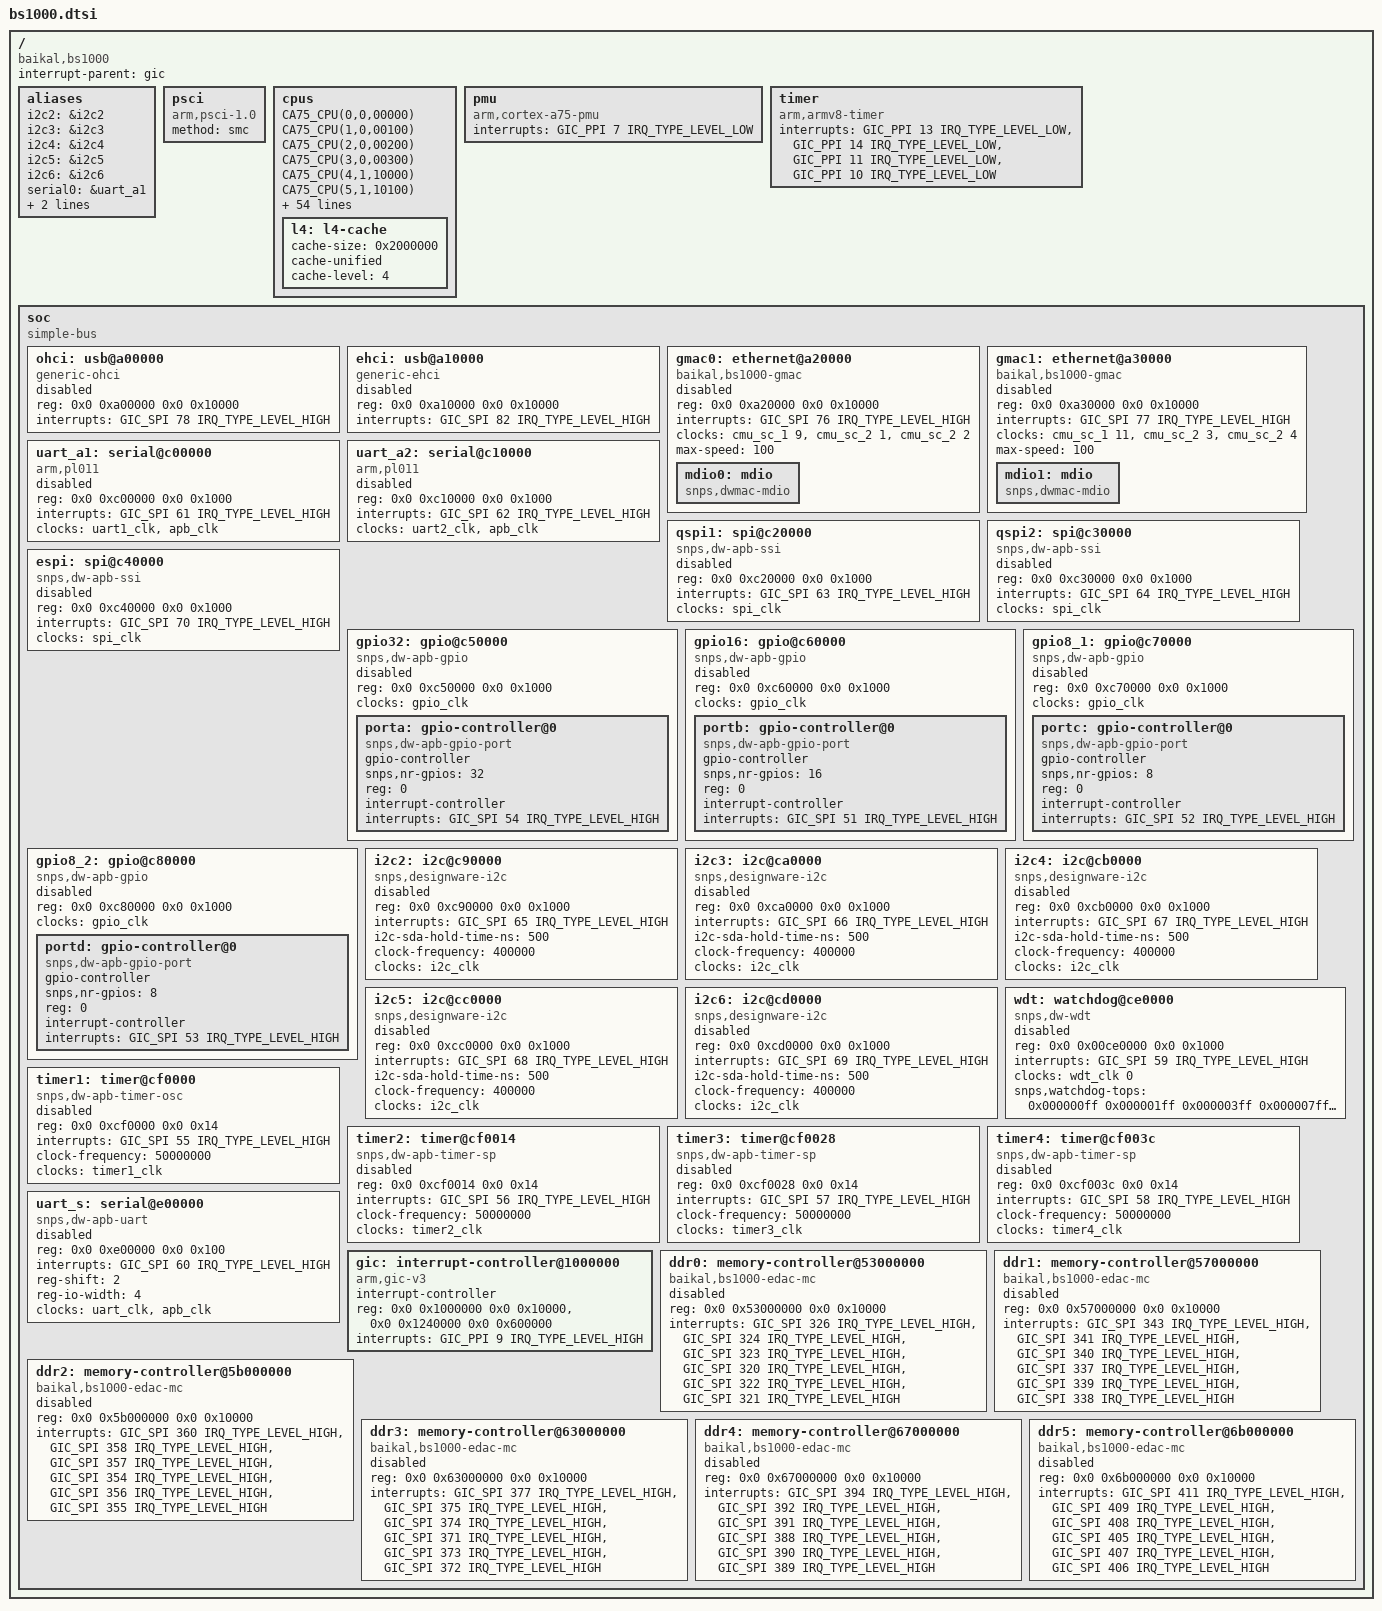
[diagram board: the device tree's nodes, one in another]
// SPDX-License-Identifier: GPL-2.0
/*
 * Device tree include file for BE-S1000 SoC
 * Copyright (C) 2021 Baikal Electronics, JSC
 */

#include <dt-bindings/interrupt-controller/arm-gic.h>
#include "bs1000-clocks.dtsi"

#define CA75_CPU(core, cluster, affinity)		\
	cpu##core: cpu@##affinity {			\
		device_type = "cpu";			\
		compatible = "arm,cortex-a75";		\
		reg = <0x0 0x##affinity>;		\
		enable-method = "psci";			\
		i-cache-size = <0x10000>;		\
		i-cache-line-size = <64>;		\
		i-cache-sets = <256>;			\
		d-cache-size = <0x10000>;		\
		d-cache-line-size = <64>;		\
		d-cache-sets = <64>;			\
		next-level-cache = <&l2_##core>;	\
		L2_CACHE(core, cluster);		\
	}

#define L2_CACHE(core, cluster)				\
	l2_##core: l2-cache {				\
		compatible = "cache";			\
		cache-size = <0x80000>;			\
		cache-line-size = <64>;			\
		cache-sets = <1024>;			\
		cache-unified;				\
		cache-level = <2>;			\
		next-level-cache = <&l3_##cluster>;	\
	}

#define L3_CACHE(cluster)				\
	l3_##cluster: l3-cache##cluster {		\
		compatible = "cache";			\
		cache-size = <0x200000>;		\
		cache-line-size = <64>;			\
		cache-sets = <2048>;			\
		cache-unified;				\
		cache-level = <3>;			\
		next-level-cache = <&l4>;		\
	}

/ {
	compatible = "baikal,bs1000";
	#address-cells = <2>;
	#size-cells = <2>;
	interrupt-parent = <&gic>;

	aliases {
		i2c2	= &i2c2;
		i2c3	= &i2c3;
		i2c4	= &i2c4;
		i2c5	= &i2c5;
		i2c6	= &i2c6;
		serial0	= &uart_a1;
		serial1	= &uart_a2;
		serial2	= &uart_s;
	};

	psci {
		compatible = "arm,psci-1.0", "arm,psci-0.2";
		method = "smc";
	};

	cpus {
		#address-cells = <2>;
		#size-cells = <0>;

		/* TODO: try to use 'cpu-map' */

		CA75_CPU(0,0,00000);
		CA75_CPU(1,0,00100);
		CA75_CPU(2,0,00200);
		CA75_CPU(3,0,00300);
		CA75_CPU(4,1,10000);
		CA75_CPU(5,1,10100);
		CA75_CPU(6,1,10200);
		CA75_CPU(7,1,10300);
		CA75_CPU(8,2,20000);
		CA75_CPU(9,2,20100);
		CA75_CPU(10,2,20200);
		CA75_CPU(11,2,20300);
		CA75_CPU(12,3,30000);
		CA75_CPU(13,3,30100);
		CA75_CPU(14,3,30200);
		CA75_CPU(15,3,30300);
		CA75_CPU(16,4,40000);
		CA75_CPU(17,4,40100);
		CA75_CPU(18,4,40200);
		CA75_CPU(19,4,40300);
		CA75_CPU(20,5,50000);
		CA75_CPU(21,5,50100);
		CA75_CPU(22,5,50200);
		CA75_CPU(23,5,50300);
		CA75_CPU(24,6,60000);
		CA75_CPU(25,6,60100);
		CA75_CPU(26,6,60200);
		CA75_CPU(27,6,60300);
		CA75_CPU(28,7,70000);
		CA75_CPU(29,7,70100);
		CA75_CPU(30,7,70200);
		CA75_CPU(31,7,70300);
		CA75_CPU(32,8,80000);
		CA75_CPU(33,8,80100);
		CA75_CPU(34,8,80200);
		CA75_CPU(35,8,80300);
		CA75_CPU(36,9,90000);
		CA75_CPU(37,9,90100);
		CA75_CPU(38,9,90200);
		CA75_CPU(39,9,90300);
		CA75_CPU(40,10,a0000);
		CA75_CPU(41,10,a0100);
		CA75_CPU(42,10,a0200);
		CA75_CPU(43,10,a0300);
		CA75_CPU(44,11,b0000);
		CA75_CPU(45,11,b0100);
		CA75_CPU(46,11,b0200);
		CA75_CPU(47,11,b0300);

		L3_CACHE(0);
		L3_CACHE(1);
		L3_CACHE(2);
		L3_CACHE(3);
		L3_CACHE(4);
		L3_CACHE(5);
		L3_CACHE(6);
		L3_CACHE(7);
		L3_CACHE(8);
		L3_CACHE(9);
		L3_CACHE(10);
		L3_CACHE(11);

		l4: l4-cache {
			cache-size = <0x2000000>;
			cache-unified;
			cache-level = <4>;
		};
	};

	pmu {
		compatible = "arm,cortex-a75-pmu", "arm,armv8-pmuv3";
		interrupts = <GIC_PPI 7 IRQ_TYPE_LEVEL_LOW>;
	};

	timer {
		compatible = "arm,armv8-timer";
		interrupts = <GIC_PPI 13 IRQ_TYPE_LEVEL_LOW>,
			     <GIC_PPI 14 IRQ_TYPE_LEVEL_LOW>,
			     <GIC_PPI 11 IRQ_TYPE_LEVEL_LOW>,
			     <GIC_PPI 10 IRQ_TYPE_LEVEL_LOW>;
	};

	soc {
		compatible = "simple-bus";
		#address-cells = <2>;
		#size-cells = <2>;
		ranges;

		ohci: usb@a00000 {
			compatible = "generic-ohci";
			reg = <0x0 0xa00000 0x0 0x10000>;
			interrupts = <GIC_SPI 78 IRQ_TYPE_LEVEL_HIGH>;
			status = "disabled";
		};

		ehci: usb@a10000 {
			compatible = "generic-ehci";
			reg = <0x0 0xa10000 0x0 0x10000>;
			interrupts = <GIC_SPI 82 IRQ_TYPE_LEVEL_HIGH>;
			status = "disabled";
		};

		gmac0: ethernet@a20000 {
			compatible = "baikal,bs1000-gmac";
			reg = <0x0 0xa20000 0x0 0x10000>;
			interrupts = <GIC_SPI 76 IRQ_TYPE_LEVEL_HIGH>;
			interrupt-names = "macirq";
			clocks = <&cmu_sc_1 9>, <&cmu_sc_2 1>, <&cmu_sc_2 2>;
			clock-names = "stmmaceth", "ptp_ref", "tx2_clk";
			max-speed = <100>;
			status = "disabled";

			mdio0: mdio {
				compatible = "snps,dwmac-mdio";
				#address-cells = <1>;
				#size-cells = <0>;
			};
		};

		gmac1: ethernet@a30000 {
			compatible = "baikal,bs1000-gmac";
			reg = <0x0 0xa30000 0x0 0x10000>;
			interrupts = <GIC_SPI 77 IRQ_TYPE_LEVEL_HIGH>;
			interrupt-names = "macirq";
			clocks = <&cmu_sc_1 11>, <&cmu_sc_2 3>, <&cmu_sc_2 4>;
			clock-names = "stmmaceth", "ptp_ref", "tx2_clk";
			max-speed = <100>;
			status = "disabled";

			mdio1: mdio {
				compatible = "snps,dwmac-mdio";
				#address-cells = <1>;
				#size-cells = <0>;
			};
		};

		uart_a1: serial@c00000 {
			compatible = "arm,pl011", "arm,primecell";
			reg = <0x0 0xc00000 0x0 0x1000>;
			interrupts = <GIC_SPI 61 IRQ_TYPE_LEVEL_HIGH>;
			clocks = <&uart1_clk>, <&apb_clk>;
			// clocks = <&cmu_sc_1 18>, <&cmu_sc_1 15>; // "lsp_uart_arm1", "lsp_apb"
			clock-names = "uartclk", "apb_pclk";
			status = "disabled";
		};

		uart_a2: serial@c10000 {
			compatible = "arm,pl011", "arm,primecell";
			reg = <0x0 0xc10000 0x0 0x1000>;
			interrupts = <GIC_SPI 62 IRQ_TYPE_LEVEL_HIGH>;
			clocks = <&uart2_clk>, <&apb_clk>;
			// clocks = <&cmu_sc_1 19>, <&cmu_sc_1 15>; // "lsp_uart_arm2", "lsp_apb"
			clock-names = "uartclk", "apb_pclk";
			status = "disabled";
		};

		qspi1: spi@c20000 {
			compatible = "snps,dw-apb-ssi";
			reg = <0x0 0xc20000 0x0 0x1000>;
			#address-cells = <1>;
			#size-cells = <0>;
			interrupts = <GIC_SPI 63 IRQ_TYPE_LEVEL_HIGH>;
			clocks = <&spi_clk>;
			// clocks = <&cmu_sc_1 20>; // "lsp_spi1"
			status = "disabled";
		};

		qspi2: spi@c30000 {
			compatible = "snps,dw-apb-ssi";
			reg = <0x0 0xc30000 0x0 0x1000>;
			#address-cells = <1>;
			#size-cells = <0>;
			interrupts = <GIC_SPI 64 IRQ_TYPE_LEVEL_HIGH>;
			clocks = <&spi_clk>;
			// clocks = <&cmu_sc_1 21>; // "lsp_spi2"
			status = "disabled";
		};

		espi: spi@c40000 {
			compatible = "snps,dw-apb-ssi";
			reg = <0x0 0xc40000 0x0 0x1000>;
			#address-cells = <1>;
			#size-cells = <0>;
			interrupts = <GIC_SPI 70 IRQ_TYPE_LEVEL_HIGH>;
			clocks = <&spi_clk>;
			// clocks = <&cmu_sc_1 22>; // "lsp_espi"
			status = "disabled";
		};

		gpio32: gpio@c50000 {
			compatible = "snps,dw-apb-gpio";
			reg = <0x0 0xc50000 0x0 0x1000>;
			#address-cells = <1>;
			#size-cells = <0>;
			clocks = <&gpio_clk>;
			// clocks = <&cmu_sc_1 16>; // "lsp_gpio_x16"
			status = "disabled";

			porta: gpio-controller@0 {
				compatible = "snps,dw-apb-gpio-port";
				gpio-controller;
				#gpio-cells = <2>;
				snps,nr-gpios = <32>;
				reg = <0>;
				interrupt-controller;
				#interrupt-cells = <2>;
				interrupts = <GIC_SPI 54 IRQ_TYPE_LEVEL_HIGH>;
			};
		};

		gpio16: gpio@c60000 {
			compatible = "snps,dw-apb-gpio";
			reg = <0x0 0xc60000 0x0 0x1000>;
			#address-cells = <1>;
			#size-cells = <0>;
			clocks = <&gpio_clk>;
			// clocks = <&cmu_sc_1 16>; // "lsp_gpio_x16"
			status = "disabled";

			portb: gpio-controller@0 {
				compatible = "snps,dw-apb-gpio-port";
				gpio-controller;
				#gpio-cells = <2>;
				snps,nr-gpios = <16>;
				reg = <0>;
				interrupt-controller;
				#interrupt-cells = <2>;
				interrupts = <GIC_SPI 51 IRQ_TYPE_LEVEL_HIGH>;
			};
		};

		gpio8_1: gpio@c70000 {
			compatible = "snps,dw-apb-gpio";
			reg = <0x0 0xc70000 0x0 0x1000>;
			#address-cells = <1>;
			#size-cells = <0>;
			clocks = <&gpio_clk>;
			// clocks = <&cmu_sc_1 16>; // "lsp_gpio_x16"
			status = "disabled";

			portc: gpio-controller@0 {
				compatible = "snps,dw-apb-gpio-port";
				gpio-controller;
				#gpio-cells = <2>;
				snps,nr-gpios = <8>;
				reg = <0>;
				interrupt-controller;
				#interrupt-cells = <2>;
				interrupts = <GIC_SPI 52 IRQ_TYPE_LEVEL_HIGH>;
			};
		};

		gpio8_2: gpio@c80000 {
			compatible = "snps,dw-apb-gpio";
			reg = <0x0 0xc80000 0x0 0x1000>;
			#address-cells = <1>;
			#size-cells = <0>;
			clocks = <&gpio_clk>;
			// clocks = <&cmu_sc_1 16>; // "lsp_gpio_x16"
			status = "disabled";

			portd: gpio-controller@0 {
				compatible = "snps,dw-apb-gpio-port";
				gpio-controller;
				#gpio-cells = <2>;
				snps,nr-gpios = <8>;
				reg = <0>;
				interrupt-controller;
				#interrupt-cells = <2>;
				interrupts = <GIC_SPI 53 IRQ_TYPE_LEVEL_HIGH>;
			};
		};

		i2c2: i2c@c90000 {
			compatible = "snps,designware-i2c";
			#address-cells = <1>;
			#size-cells = <0>;
			reg = <0x0 0xc90000 0x0 0x1000>;
			interrupts = <GIC_SPI 65 IRQ_TYPE_LEVEL_HIGH>;
			i2c-sda-hold-time-ns = <500>;
			clock-frequency = <400000>;
			clocks = <&i2c_clk>;
			// clocks = <&cmu_sc_1 23>; // "lsp_smbus_i2c1"
			clock-names = "soc_i2cclk";
			status = "disabled";
		};

		i2c3: i2c@ca0000 {
			compatible = "snps,designware-i2c";
			#address-cells = <1>;
			#size-cells = <0>;
			reg = <0x0 0xca0000 0x0 0x1000>;
			interrupts = <GIC_SPI 66 IRQ_TYPE_LEVEL_HIGH>;
			i2c-sda-hold-time-ns = <500>;
			clock-frequency = <400000>;
			clocks = <&i2c_clk>;
			// clocks = <&cmu_sc_1 24>; // "lsp_smbus_i2c2"
			clock-names = "soc_i2cclk";
			status = "disabled";
		};

		i2c4: i2c@cb0000 {
			compatible = "snps,designware-i2c";
			#address-cells = <1>;
			#size-cells = <0>;
			reg = <0x0 0xcb0000 0x0 0x1000>;
			interrupts = <GIC_SPI 67 IRQ_TYPE_LEVEL_HIGH>;
			i2c-sda-hold-time-ns = <500>;
			clock-frequency = <400000>;
			clocks = <&i2c_clk>;
			// clocks = <&cmu_sc_1 25>; // "lsp_smbus_i2c3"
			clock-names = "soc_i2cclk";
			status = "disabled";
		};

		i2c5: i2c@cc0000 {
			compatible = "snps,designware-i2c";
			#address-cells = <1>;
			#size-cells = <0>;
			reg = <0x0 0xcc0000 0x0 0x1000>;
			interrupts = <GIC_SPI 68 IRQ_TYPE_LEVEL_HIGH>;
			i2c-sda-hold-time-ns = <500>;
			clock-frequency = <400000>;
			clocks = <&i2c_clk>;
			// clocks = <&cmu_sc_1 26>; // "lsp_smbus_i2c4"
			clock-names = "soc_i2cclk";
			status = "disabled";
		};

		i2c6: i2c@cd0000 {
			compatible = "snps,designware-i2c";
			#address-cells = <1>;
			#size-cells = <0>;
			reg = <0x0 0xcd0000 0x0 0x1000>;
			interrupts = <GIC_SPI 69 IRQ_TYPE_LEVEL_HIGH>;
			i2c-sda-hold-time-ns = <500>;
			clock-frequency = <400000>;
			clocks = <&i2c_clk>;
			// clocks = <&cmu_sc_1 27>; // "lsp_smbus_i2c5"
			clock-names = "soc_i2cclk";
			status = "disabled";
		};

		wdt: watchdog@ce0000 {
			compatible = "snps,dw-wdt";
			reg = <0x0 0x00ce0000 0x0 0x1000>;
			interrupts = <GIC_SPI 59 IRQ_TYPE_LEVEL_HIGH>;
			clocks = <&wdt_clk 0>;
			// clocks = <&cmu_sc_1 32>; // "lsp_wdt_x16"
			clock-names = "wdtclk";
			snps,watchdog-tops = <0x000000ff 0x000001ff 0x000003ff 0x000007ff
					      0x0000ffff 0x0001ffff 0x0003ffff 0x0007ffff
					      0x000fffff 0x001fffff 0x003fffff 0x007fffff
					      0x00ffffff 0x01ffffff 0x03ffffff 0x07ffffff>;
			status = "disabled";
		};

		timer1: timer@cf0000 {
			compatible = "snps,dw-apb-timer-osc";
			reg = <0x0 0xcf0000 0x0 0x14>;
			interrupts = <GIC_SPI 55 IRQ_TYPE_LEVEL_HIGH>;
			clock-frequency = <50000000>;
			clocks = <&timer1_clk>;
			// clocks = <&cmu_sc_1 28>; // "lsp_timer1"
			clock-names = "soc_timer1clk";
			status = "disabled";
		};

		timer2: timer@cf0014 {
			compatible = "snps,dw-apb-timer-sp";
			reg = <0x0 0xcf0014 0x0 0x14>;
			interrupts = <GIC_SPI 56 IRQ_TYPE_LEVEL_HIGH>;
			clock-frequency = <50000000>;
			clocks = <&timer2_clk>;
			// clocks = <&cmu_sc_1 29>; // "lsp_timer2"
			clock-names = "soc_timer2clk";
			status = "disabled";
		};

		timer3: timer@cf0028 {
			compatible = "snps,dw-apb-timer-sp";
			reg = <0x0 0xcf0028 0x0 0x14>;
			interrupts = <GIC_SPI 57 IRQ_TYPE_LEVEL_HIGH>;
			clock-frequency = <50000000>;
			clocks = <&timer3_clk>;
			// clocks = <&cmu_sc_1 30>; // "lsp_timer3"
			clock-names = "soc_timer3clk";
			status = "disabled";
		};

		timer4: timer@cf003c {
			compatible = "snps,dw-apb-timer-sp";
			reg = <0x0 0xcf003c 0x0 0x14>;
			interrupts = <GIC_SPI 58 IRQ_TYPE_LEVEL_HIGH>;
			clock-frequency = <50000000>;
			clocks = <&timer4_clk>;
			//clocks = <&cmu_sc_1 31>; // "lsp_timer4"
			clock-names = "soc_timer4clk";
			status = "disabled";
		};

		uart_s: serial@e00000 {
			compatible = "snps,dw-apb-uart";
			reg = <0x0 0xe00000 0x0 0x100>;
			interrupts = <GIC_SPI 60 IRQ_TYPE_LEVEL_HIGH>;
			reg-shift = <2>;
			reg-io-width = <4>;
			clocks = <&uart_clk>, <&apb_clk>;
			// clocks = <&cmu_sc_1 17>, <&cmu_sc_1 15>; // "lsp_uart", "lsp_apb"
			clock-names = "uartclk", "apb_pclk";
			status = "disabled";
		};

		gic: interrupt-controller@1000000 {
			compatible = "arm,gic-v3";
			#interrupt-cells = <3>;
			#address-cells = <2>;
			#size-cells = <2>;
			ranges;
			interrupt-controller;
			reg = <0x0 0x1000000 0x0 0x10000>,  /* GICD */
			      <0x0 0x1240000 0x0 0x600000>; /* GICR */
			      /* TODO: optional ranges - GICC, GICH, GICV */
			interrupts = <GIC_PPI 9 IRQ_TYPE_LEVEL_HIGH>;

			/* TODO: GIC.v3 Interrupt Translation Service */
		};

		ddr0: memory-controller@53000000 {
			compatible = "baikal,bs1000-edac-mc";
			reg = <0x0 0x53000000 0x0 0x10000>;
			interrupts = <GIC_SPI 326 IRQ_TYPE_LEVEL_HIGH>, /* dfi_alert_err */
				     <GIC_SPI 324 IRQ_TYPE_LEVEL_HIGH>, /* ecc_corrected_err */
				     <GIC_SPI 323 IRQ_TYPE_LEVEL_HIGH>, /* ecc_uncorrected_err */
				     <GIC_SPI 320 IRQ_TYPE_LEVEL_HIGH>, /* sbr_done */
				     <GIC_SPI 322 IRQ_TYPE_LEVEL_HIGH>, /* ecc_corrected_err_fault */
				     <GIC_SPI 321 IRQ_TYPE_LEVEL_HIGH>; /* ecc_uncorrected_err_fault */
			// clocks = <&cmu_ddr_0 0>;
			// clock-names = "apb_pclk";
			status = "disabled";
		};

		ddr1: memory-controller@57000000 {
			compatible = "baikal,bs1000-edac-mc";
			reg = <0x0 0x57000000 0x0 0x10000>;
			interrupts = <GIC_SPI 343 IRQ_TYPE_LEVEL_HIGH>, /* dfi_alert_err */
				     <GIC_SPI 341 IRQ_TYPE_LEVEL_HIGH>, /* ecc_corrected_err */
				     <GIC_SPI 340 IRQ_TYPE_LEVEL_HIGH>, /* ecc_uncorrected_err */
				     <GIC_SPI 337 IRQ_TYPE_LEVEL_HIGH>, /* sbr_done */
				     <GIC_SPI 339 IRQ_TYPE_LEVEL_HIGH>, /* ecc_corrected_err_fault */
				     <GIC_SPI 338 IRQ_TYPE_LEVEL_HIGH>; /* ecc_uncorrected_err_fault */
			// clocks = <&cmu_ddr_1 0>;
			// clock-names = "apb_pclk";
			status = "disabled";
		};

		ddr2: memory-controller@5b000000 {
			compatible = "baikal,bs1000-edac-mc";
			reg = <0x0 0x5b000000 0x0 0x10000>;
			interrupts = <GIC_SPI 360 IRQ_TYPE_LEVEL_HIGH>, /* dfi_alert_err */
				     <GIC_SPI 358 IRQ_TYPE_LEVEL_HIGH>, /* ecc_corrected_err */
				     <GIC_SPI 357 IRQ_TYPE_LEVEL_HIGH>, /* ecc_uncorrected_err */
				     <GIC_SPI 354 IRQ_TYPE_LEVEL_HIGH>, /* sbr_done */
				     <GIC_SPI 356 IRQ_TYPE_LEVEL_HIGH>, /* ecc_corrected_err_fault */
				     <GIC_SPI 355 IRQ_TYPE_LEVEL_HIGH>; /* ecc_uncorrected_err_fault */
			// clocks = <&cmu_ddr_2 0>;
			// clock-names = "apb_pclk";
			status = "disabled";
		};

		ddr3: memory-controller@63000000 {
			compatible = "baikal,bs1000-edac-mc";
			reg = <0x0 0x63000000 0x0 0x10000>;
			interrupts = <GIC_SPI 377 IRQ_TYPE_LEVEL_HIGH>, /* dfi_alert_err */
				     <GIC_SPI 375 IRQ_TYPE_LEVEL_HIGH>, /* ecc_corrected_err */
				     <GIC_SPI 374 IRQ_TYPE_LEVEL_HIGH>, /* ecc_uncorrected_err */
				     <GIC_SPI 371 IRQ_TYPE_LEVEL_HIGH>, /* sbr_done */
				     <GIC_SPI 373 IRQ_TYPE_LEVEL_HIGH>, /* ecc_corrected_err_fault */
				     <GIC_SPI 372 IRQ_TYPE_LEVEL_HIGH>; /* ecc_uncorrected_err_fault */
			// clocks = <&cmu_ddr_3 0>;
			// clock-names = "apb_pclk";
			status = "disabled";
		};

		ddr4: memory-controller@67000000 {
			compatible = "baikal,bs1000-edac-mc";
			reg = <0x0 0x67000000 0x0 0x10000>;
			interrupts = <GIC_SPI 394 IRQ_TYPE_LEVEL_HIGH>, /* dfi_alert_err */
				     <GIC_SPI 392 IRQ_TYPE_LEVEL_HIGH>, /* ecc_corrected_err */
				     <GIC_SPI 391 IRQ_TYPE_LEVEL_HIGH>, /* ecc_uncorrected_err */
				     <GIC_SPI 388 IRQ_TYPE_LEVEL_HIGH>, /* sbr_done */
				     <GIC_SPI 390 IRQ_TYPE_LEVEL_HIGH>, /* ecc_corrected_err_fault */
				     <GIC_SPI 389 IRQ_TYPE_LEVEL_HIGH>; /* ecc_uncorrected_err_fault */
			// clocks = <&cmu_ddr_4 0>;
			// clock-names = "apb_pclk";
			status = "disabled";
		};

		ddr5: memory-controller@6b000000 {
			compatible = "baikal,bs1000-edac-mc";
			reg = <0x0 0x6b000000 0x0 0x10000>;
			interrupts = <GIC_SPI 411 IRQ_TYPE_LEVEL_HIGH>, /* dfi_alert_err */
				     <GIC_SPI 409 IRQ_TYPE_LEVEL_HIGH>, /* ecc_corrected_err */
				     <GIC_SPI 408 IRQ_TYPE_LEVEL_HIGH>, /* ecc_uncorrected_err */
				     <GIC_SPI 405 IRQ_TYPE_LEVEL_HIGH>, /* sbr_done */
				     <GIC_SPI 407 IRQ_TYPE_LEVEL_HIGH>, /* ecc_corrected_err_fault */
				     <GIC_SPI 406 IRQ_TYPE_LEVEL_HIGH>; /* ecc_uncorrected_err_fault */
			// clocks = <&cmu_ddr_5 0>;
			// clock-names = "apb_pclk";
			status = "disabled";
		};
	};
};
